# i2c register map
Vendor: Texas Instruments
Peripheral module from a debugger description file (folder Keystone2).
Registers are 32-bit, read-write, no defined reset value unless marked. A register's access mark holds for its fields unless they carry their own. Offsets are as the file gives them; lines under a group give offsets from that group; [hi:lo] are bit positions; {n}, {i} and the like mark numbered series; 'fields as' and 'values as' point back to an identical list; <NAME> marks a mode.

## I2C_2
0x00 icoar
  [9:0] oaddr
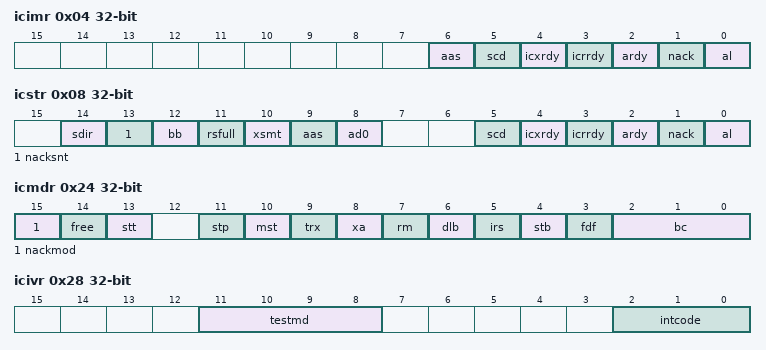
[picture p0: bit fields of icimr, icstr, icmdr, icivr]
0x04 icimr
  [6] aas, [5] scd, [4] icxrdy, [3] icrrdy, [2] ardy, [1] nack, [0] al
0x08 icstr
  [14] sdir, [13] nacksnt, [12] bb, [11] rsfull, [10] xsmt, [9] aas, [8] ad0, [5] scd, [4] icxrdy, [3] icrrdy, [2] ardy, [1] nack, [0] al
0x0C icclkl
  [15:0] iccl
0x10 icclkh
  [15:0] icch
0x14 iccnt
  [15:0] icdc
0x18 icdrr
  [7:0] d
0x1C icsar
  [9:0] saddr
0x20 icdxr
  [7:0] d
0x24 icmdr
  [15] nackmod, [14] free, [13] stt, [11] stp, [10] mst, [9] trx, [8] xa, [7] rm, [6] dlb, [5] irs, [4] stb, [3] fdf, [2:0] bc
0x28 icivr
  [11:8] testmd, [2:0] intcode
0x2C icemdr
  [0] bcm
0x30 icpsc
  [7:0] ipsc
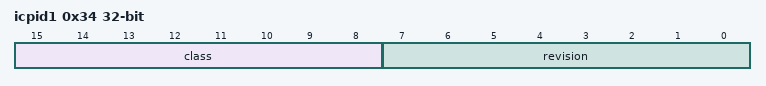
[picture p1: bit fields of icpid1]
0x34 icpid1
  [15:8] class, [7:0] revision
0x38 icpid2
  [7:0] type
